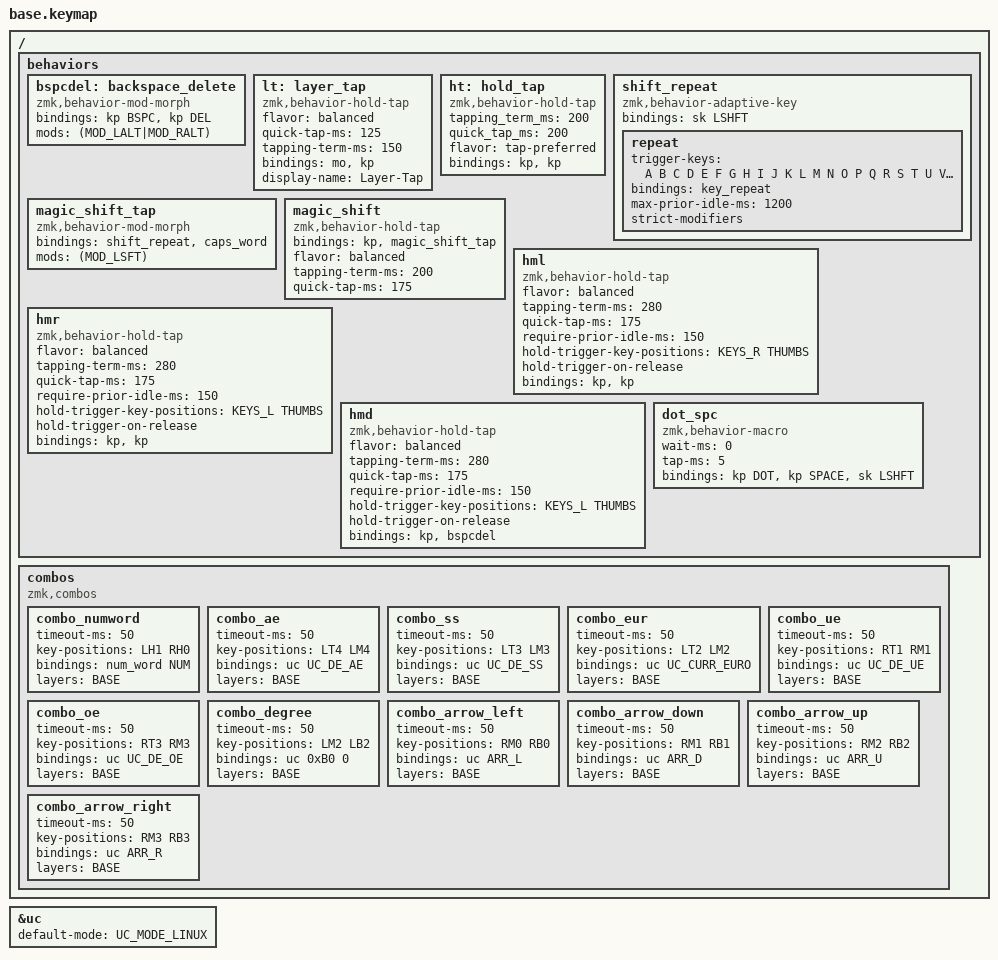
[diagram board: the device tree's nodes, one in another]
#include <behaviors.dtsi>
#include <dt-bindings/zmk/bt.h>
#include <dt-bindings/zmk/ext_power.h>
#include <dt-bindings/zmk/keys.h>
#include <dt-bindings/zmk/outputs.h>
#include <dt-bindings/zmk/pointing.h>

#include <behaviors/num_word.dtsi>
#include <behaviors/unicode.dtsi>

#include <zmk-unicode/keys/german.h>
#include <zmk-unicode/keys/currency.h>

#include "zmk-helpers/helper.h"

&uc {
    default-mode = <UC_MODE_LINUX>;
};

#define ___ &trans
#define XXX &none

#define PASTE LC(LS(V))
#define CANCEL &kp K_CANCEL // Cancel caps-word & auto-layers.

#define BASE 0
#define NUM 1
#define SYMBOL 2
#define NAV 3
#define MOUSE 4
#define EMOJI 5
#define GAMING 6
#define GAMING2 7
#define SYS 8

// Arrow aliases for use with &uc (tap / shift-tap)
#define ARR_L  0x2190  0x21D0  // ← / ⇐
#define ARR_D  0x2193  0x21D3  // ↓ / ⇓
#define ARR_U  0x2191  0x21D1  // ↑ / ⇑
#define ARR_R  0x2192  0x21D2  // → / ⇒

// Default ZMK_BASE_LAYER for 36-key boards (flat, no padding).
// Define this macro before including this file for board-specific layouts.
#ifndef ZMK_BASE_LAYER
#  define ZMK_BASE_LAYER(name, LT, RT, LM, RM, LB, RB, LH, RH) \
       ZMK_LAYER(name, LT RT LM RM LB RB LH RH)
#endif

/ {
    behaviors {
        bspcdel: backspace_delete {
            compatible = "zmk,behavior-mod-morph";
            #binding-cells = <0>;
            bindings = <&kp BSPC>, <&kp DEL>;
            mods = <(MOD_LALT|MOD_RALT)>;
        };
        lt: layer_tap {
            compatible = "zmk,behavior-hold-tap";
            #binding-cells = <2>;
            flavor = "balanced";
            quick-tap-ms = <125>;
            tapping-term-ms = <150>;
            bindings = <&mo>, <&kp>;
            display-name = "Layer-Tap";
        };
        ht: hold_tap {
            compatible = "zmk,behavior-hold-tap";
            #binding-cells = <2>;
            tapping_term_ms = <200>;
            quick_tap_ms = <200>;
            flavor = "tap-preferred";
            bindings = <&kp>, <&kp>;
        };
    };
};

/ {
    combos {
        compatible = "zmk,combos";

        combo_numword {
            timeout-ms = <50>;
            key-positions = <LH1 RH0>;
            bindings = <&num_word NUM>;
            layers = <BASE>;
        };

        combo_ae {
            timeout-ms = <50>;
            key-positions = <LT4 LM4>;
            bindings = <&uc UC_DE_AE>;
            layers = <BASE>;
        };

        combo_ss {
            timeout-ms = <50>;
            key-positions = <LT3 LM3>;
            bindings = <&uc UC_DE_SS>;
            layers = <BASE>;
        };

        combo_eur {
            timeout-ms = <50>;
            key-positions = <LT2 LM2>;
            bindings = <&uc UC_CURR_EURO>;
            layers = <BASE>;
        };

        combo_ue {
            timeout-ms = <50>;
            key-positions = <RT1 RM1>;
            bindings = <&uc UC_DE_UE>;
            layers = <BASE>;
        };

        combo_oe {
            timeout-ms = <50>;
            key-positions = <RT3 RM3>;
            bindings = <&uc UC_DE_OE>;
            layers = <BASE>;
        };

        combo_degree {
            timeout-ms = <50>;
            key-positions = <LM2 LB2>;
            bindings = <&uc 0xB0 0>;  // °
            layers = <BASE>;
        };

        combo_arrow_left {
            timeout-ms = <50>;
            key-positions = <RM0 RB0>;
            bindings = <&uc ARR_L>;  // ← / ⇐
            layers = <BASE>;
        };

        combo_arrow_down {
            timeout-ms = <50>;
            key-positions = <RM1 RB1>;
            bindings = <&uc ARR_D>;  // ↓ / ⇓
            layers = <BASE>;
        };

        combo_arrow_up {
            timeout-ms = <50>;
            key-positions = <RM2 RB2>;
            bindings = <&uc ARR_U>;  // ↑ / ⇑
            layers = <BASE>;
        };

        combo_arrow_right {
            timeout-ms = <50>;
            key-positions = <RM3 RB3>;
            bindings = <&uc ARR_R>;  // → / ⇒
            layers = <BASE>;
        };
    };
};

#define MAGIC_SHIFT &magic_shift LSHFT 0
ZMK_ADAPTIVE_KEY(shift_repeat,
    bindings = <&sk LSHFT>;
    repeat {
        trigger-keys = <A B C D E F G H I J K L M N O P Q R S T U V W X Y Z>;
        bindings = <&key_repeat>;
        max-prior-idle-ms = <1200>;
        strict-modifiers;
    };
)

ZMK_MOD_MORPH(magic_shift_tap,
    bindings = <&shift_repeat>, <&caps_word>;
    mods = <(MOD_LSFT)>;
)

ZMK_HOLD_TAP(magic_shift,
    bindings = <&kp>, <&magic_shift_tap>;
    flavor = "balanced";
    tapping-term-ms = <200>;
    quick-tap-ms = <175>;
)

ZMK_HOLD_TAP(hml,
    flavor = "balanced";
    tapping-term-ms = <280>;
    quick-tap-ms = <175>;
    require-prior-idle-ms = <150>;
    hold-trigger-key-positions = <KEYS_R THUMBS>;
    hold-trigger-on-release;
    bindings = <&kp>, <&kp>;
)

ZMK_HOLD_TAP(hmr,
    flavor = "balanced";
    tapping-term-ms = <280>;
    quick-tap-ms = <175>;
    require-prior-idle-ms = <150>;
    hold-trigger-key-positions = <KEYS_L THUMBS>;
    hold-trigger-on-release;
    bindings = <&kp>, <&kp>;
)

ZMK_HOLD_TAP(hmd,
    flavor = "balanced";
    tapping-term-ms = <280>;
    quick-tap-ms = <175>;
    require-prior-idle-ms = <150>;
    hold-trigger-key-positions = <KEYS_L THUMBS>;
    hold-trigger-on-release;
    bindings = <&kp>, <&bspcdel>;
)

// Sentence end: dot -> space -> sticky shift
ZMK_MACRO(dot_spc,
    wait-ms = <0>;
    tap-ms = <5>;
    bindings = <&kp DOT &kp SPACE &sk LSHFT>;
)

ZMK_CONDITIONAL_LAYER(sys, MOUSE NUM, SYS)

ZMK_BASE_LAYER(Base,
//╭───────────────┬───────────────┬───────────────┬───────────────┬───────────────╮   ╭───────────────┬───────────────┬───────────────┬───────────────┬───────────────╮
    &kp Q           &kp W           &kp E           &kp R           &kp T,              &kp Y           &kp U           &kp I           &kp O           &kp P,
//├───────────────┼───────────────┼───────────────┼───────────────┼───────────────┤   ├───────────────┼───────────────┼───────────────┼───────────────┼───────────────┤
    &hml LGUI A     &hml LALT S     &hml LSHFT D    &hml LCTRL F    &kp G,              &kp H           &hmr LCTRL J    &hmr RSHFT K    &hmr LALT L     &hmd LGUI 0,
//├───────────────┼───────────────┼───────────────┼───────────────┼───────────────┤   ├───────────────┼───────────────┼───────────────┼───────────────┼───────────────┤
    &kp Z           &ht K_CUT X     &ht K_COPY C    &ht PASTE V     &kp B,              &kp N           &kp M           &kp COMMA       &kp DOT         &kp FSLH,
//╰───────────────┴───────────────┼───────────────┼───────────────┼───────────────┤   ├───────────────┼───────────────┼───────────────┼───────────────┴───────────────╯
                                    &lt MOUSE TAB   &lt NUM ESC     &lt NAV SPACE,      &lt SYMBOL RET  MAGIC_SHIFT     &lt EMOJI DEL
//                                ╰───────────────┴───────────────┴───────────────╯   ╰───────────────┴───────────────┴───────────────╯
)

ZMK_BASE_LAYER(Num,
//╭───────────────┬───────────────┬───────────────┬───────────────┬───────────────╮   ╭───────────────┬───────────────┬───────────────┬───────────────┬───────────────╮
    &kp F9          &kp F10         &kp F11         &kp F12         ___,                &kp PLUS        &kp N7          &kp N8          &kp N9          &kp MINUS,
//├───────────────┼───────────────┼───────────────┼───────────────┼───────────────┤   ├───────────────┼───────────────┼───────────────┼───────────────┼───────────────┤
    &hml LGUI F5    &hml LALT F6    &hml LSHFT F7   &hml LCTRL F8   ___,                &kp DOT         &hmr LCTRL N4   &hmr RSHFT N5   &hmr LALT N6    &hmd LGUI 0,
//├───────────────┼───────────────┼───────────────┼───────────────┼───────────────┤   ├───────────────┼───────────────┼───────────────┼───────────────┼───────────────┤
    &kp F1          &kp F2          &kp F3          &kp F4          ___,                &kp ASTERISK    &kp N1          &kp N2          &kp N3          &kp SLASH,
//╰───────────────┴───────────────┼───────────────┼───────────────┼───────────────┤   ├───────────────┼───────────────┼───────────────┼───────────────┴───────────────╯
                                    ___             ___             ___,                &kp EQUAL       &kp N0          ___
//                                ╰───────────────┴───────────────┴───────────────╯   ╰───────────────┴───────────────┴───────────────╯
)

ZMK_BASE_LAYER(Symbol,
//╭───────────────┬───────────────┬───────────────┬───────────────┬───────────────╮   ╭───────────────┬───────────────┬───────────────┬───────────────┬───────────────╮
    &kp EXCL        &kp PLUS        &kp LT          &kp GT          &kp TILDE,          &kp CARET       &kp LBRC        &kp RBRC        &kp DLLR        &kp BSLH,
//├───────────────┼───────────────┼───────────────┼───────────────┼───────────────┤   ├───────────────┼───────────────┼───────────────┼───────────────┼───────────────┤
    &hml LGUI UNDER &hml LALT MINUS &hml LSHFT LBKT &hml LCTRL RBKT &kp EQUAL,          &kp PIPE        &hmr LCTRL LPAR &hmr RSHFT RPAR &hmr LALT SEMI  &hmr LGUI COLON,
//├───────────────┼───────────────┼───────────────┼───────────────┼───────────────┤   ├───────────────┼───────────────┼───────────────┼───────────────┼───────────────┤
    &kp QMARK       &kp ASTERISK    &kp HASH        &kp PERCENT     &kp AT,             &kp AMPS        &kp SQT         &kp DQT         &kp GRAVE       &kp SLASH,
//╰───────────────┴───────────────┼───────────────┼───────────────┼───────────────┤   ├───────────────┼───────────────┼───────────────┼───────────────┴───────────────╯
                                    ___             ___             &dot_spc,           ___             ___             ___
//                                ╰───────────────┴───────────────┴───────────────╯   ╰───────────────┴───────────────┴───────────────╯
)

ZMK_BASE_LAYER(Nav,
//╭───────────────┬───────────────┬───────────────┬───────────────┬───────────────╮   ╭───────────────┬───────────────┬───────────────┬───────────────┬───────────────╮
    ___             ___             ___             ___             ___,                &kp HOME         &kp PGDN       &kp PGUP        &kp END         ___,
//├───────────────┼───────────────┼───────────────┼───────────────┼───────────────┤   ├───────────────┼───────────────┼───────────────┼───────────────┼───────────────┤
    &kp LGUI        &kp LALT        &kp LSHFT       &kp LCTRL       ___,                &kp LEFT         &kp DOWN       &kp UP          &kp RIGHT       ___,
//├───────────────┼───────────────┼───────────────┼───────────────┼───────────────┤   ├───────────────┼───────────────┼───────────────┼───────────────┼───────────────┤
    ___             ___             ___             ___             ___,                &kp C_PREVIOUS   &kp C_VOL_DN   &kp C_VOL_UP    &kp C_NEXT      ___,
//╰───────────────┴───────────────┼───────────────┼───────────────┼───────────────┤   ├───────────────┼───────────────┼───────────────┼───────────────┴───────────────╯
                                    ___             ___             ___,                &kp C_PLAY_PAUSE &kp C_MUTE     CANCEL
//                                ╰───────────────┴───────────────┴───────────────╯   ╰───────────────┴───────────────┴───────────────╯
)

ZMK_BASE_LAYER(Mouse,
//╭───────────────┬───────────────┬───────────────┬───────────────┬───────────────╮   ╭───────────────┬───────────────┬───────────────┬───────────────┬───────────────╮
    ___             ___             ___             ___             ___,                &msc SCRL_LEFT  &msc SCRL_DOWN  &msc SCRL_UP    &msc SCRL_RIGHT ___,
//├───────────────┼───────────────┼───────────────┼───────────────┼───────────────┤   ├───────────────┼───────────────┼───────────────┼───────────────┼───────────────┤
    &kp LGUI        &kp LALT        &kp LSHFT       &kp LCTRL       ___,                &mmv MOVE_LEFT  &mmv MOVE_DOWN  &mmv MOVE_UP    &mmv MOVE_RIGHT ___,
//├───────────────┼───────────────┼───────────────┼───────────────┼───────────────┤   ├───────────────┼───────────────┼───────────────┼───────────────┼───────────────┤
    ___             ___             ___             ___             ___,                ___             ___             ___             ___             ___,
//╰───────────────┴───────────────┼───────────────┼───────────────┼───────────────┤   ├───────────────┼───────────────┼───────────────┼───────────────┴───────────────╯
                                    ___             ___             ___,                &mkp MB1        &mkp MB2        &mkp MB3
//                                ╰───────────────┴───────────────┴───────────────╯   ╰───────────────┴───────────────┴───────────────╯
)

ZMK_BASE_LAYER(Emoji,
//╭───────────────┬───────────────┬───────────────┬───────────────┬───────────────╮   ╭───────────────┬───────────────┬───────────────┬───────────────┬───────────────╮
    &uc 0x2753 0    &uc 0x1F44B 0   &uc 0x1F440 0   &uc 0x1F680 0   &uc 0x1F622 0,      &uc 0x1F389 0   &uc 0x1F44D 0   &uc 0x1F607 0   &uc 0x1F44C 0   &uc 0x1F64F 0,
//  ❓              👋              👀              🚀              😢                  🎉              👍              😇              👌              🙏
//├───────────────┼───────────────┼───────────────┼───────────────┼───────────────┤   ├───────────────┼───────────────┼───────────────┼───────────────┼───────────────┤
    &uc 0x1F44F 0   &uc 0x1F605 0   &uc 0x1F44E 0   &uc 0x1F525 0   &uc 0x1F62C 0,      &uc 0x2764 0    &uc 0x1F602 0   &uc 0x1F618 0   &uc 0x1F923 0   ___,
//  👏              😅              👎              🔥              😬                  ❤️              😂              😘              🤣
//├───────────────┼───────────────┼───────────────┼───────────────┼───────────────┤   ├───────────────┼───────────────┼───────────────┼───────────────┼───────────────┤
    &uc 0x1F4A4 0   &uc 0x274C 0    &uc 0x2705 0    &uc 0x270C 0    &uc 0x1F60A 0,      &uc 0x1F937 0   &uc 0x1F648 0   &uc 0x1F61C 0   &uc 0x1F61B 0   &uc 0x1F4AA 0,
//  💤              ❌              ✅              ✌️              😊                  🤷              🙈              😜              😛              💪
//╰───────────────┴───────────────┼───────────────┼───────────────┼───────────────┤   ├───────────────┼───────────────┼───────────────┼───────────────┴───────────────╯
                                    ___             ___             ___,                ___             ___             ___
//                                ╰───────────────┴───────────────┴───────────────╯   ╰───────────────┴───────────────┴───────────────╯
)

ZMK_BASE_LAYER(Gaming,
//╭───────────────┬───────────────┬───────────────┬───────────────┬───────────────╮   ╭───────────────┬───────────────┬───────────────┬───────────────┬───────────────╮
    &kp ESC         &kp N1          &kp N2          &kp N3          &kp N4,             &kp Y           &kp U           &kp I           &kp O           &kp P,
//├───────────────┼───────────────┼───────────────┼───────────────┼───────────────┤   ├───────────────┼───────────────┼───────────────┼───────────────┼───────────────┤
    &kp TAB         &kp Q           &kp W           &kp E           &kp R,              &kp H           &kp J           &kp K           &kp L           &bspcdel,
//├───────────────┼───────────────┼───────────────┼───────────────┼───────────────┤   ├───────────────┼───────────────┼───────────────┼───────────────┼───────────────┤
    &kp LSHFT       &kp A           &kp S           &kp D           &kp F,              &kp N           &kp M           &kp COMMA       &kp DOT         &kp FSLH,
//╰───────────────┴───────────────┼───────────────┼───────────────┼───────────────┤   ├───────────────┼───────────────┼───────────────┼───────────────┴───────────────╯
                                    &kp LCTRL       &mo GAMING2     &kp SPACE,          &kp RET         &kp ESC         &tog GAMING
//                                ╰───────────────┴───────────────┴───────────────╯   ╰───────────────┴───────────────┴───────────────╯
)

ZMK_BASE_LAYER(Gaming2,
//╭───────────────┬───────────────┬───────────────┬───────────────┬───────────────╮   ╭───────────────┬───────────────┬───────────────┬───────────────┬───────────────╮
    &kp N5          &kp N6          &kp N7          &kp N8          &kp N9,             ___             ___             ___             ___             ___,
//├───────────────┼───────────────┼───────────────┼───────────────┼───────────────┤   ├───────────────┼───────────────┼───────────────┼───────────────┼───────────────┤
    &kp LALT        &kp G           ___             &kp C           &kp M,                ___             ___             ___             ___             ___,
//├───────────────┼───────────────┼───────────────┼───────────────┼───────────────┤   ├───────────────┼───────────────┼───────────────┼───────────────┼───────────────┤
    ___             ___             ___             ___             &kp B,              ___             ___             ___             ___             ___,
//╰───────────────┴───────────────┼───────────────┼───────────────┼───────────────┤   ├───────────────┼───────────────┼───────────────┼───────────────┴───────────────╯
                                    &kp Z           ___             ___,                ___             ___             ___
//                                ╰───────────────┴───────────────┴───────────────╯   ╰───────────────┴───────────────┴───────────────╯
)

ZMK_BASE_LAYER(Sys,
//╭───────────────┬───────────────┬───────────────┬───────────────┬───────────────╮   ╭───────────────┬───────────────┬───────────────┬───────────────┬───────────────╮
    &bt BT_SEL 0    &bt BT_SEL 1    &bt BT_SEL 2    &bt BT_SEL 3    &bt BT_SEL 4,       &bt BT_CLR      &out OUT_USB    ___             ___             ___,
//├───────────────┼───────────────┼───────────────┼───────────────┼───────────────┤   ├───────────────┼───────────────┼───────────────┼───────────────┼───────────────┤
    &sys_reset      ___             ___             &bootloader     ___         ,       ___             &bootloader     ___             ___             &sys_reset,
//├───────────────┼───────────────┼───────────────┼───────────────┼───────────────┤   ├───────────────┼───────────────┼───────────────┼───────────────┼───────────────┤
    ___             ___             ___             ___             &out OUT_BLE,       ___             ___             ___             ___             ___,
//╰───────────────┴───────────────┼───────────────┼───────────────┼───────────────┤   ├───────────────┼───────────────┼───────────────┼───────────────┴───────────────╯
                                    ___             ___             ___,                &tog GAMING     ___             ___
//                                ╰───────────────┴───────────────┴───────────────╯   ╰───────────────┴───────────────┴───────────────╯
)

/* vim: set ft=c tw=146: */
